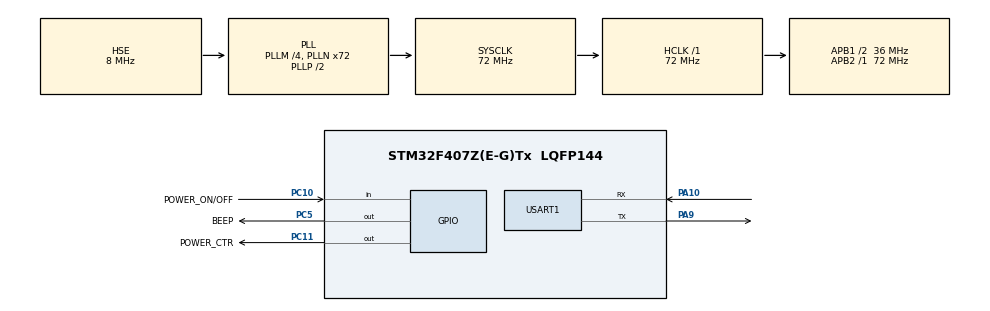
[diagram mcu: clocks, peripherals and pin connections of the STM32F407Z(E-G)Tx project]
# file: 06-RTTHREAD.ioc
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Mcu.Family=STM32F4
Mcu.Name=STM32F407Z(E-G)Tx
Mcu.Package=LQFP144
NVIC.PriorityGroup=NVIC_PRIORITYGROUP_4
NVIC.TIM7_IRQn=true\:15\:0\:false\:false\:true\:false\:false\:true\:true
NVIC.TimeBase=TIM7_IRQn
NVIC.TimeBaseIP=TIM7
NVIC.USART1_IRQn=true\:0\:0\:false\:false\:true\:false\:true\:true\:true
PA10.Mode=Asynchronous
PA10.Signal=USART1_RX
PA13.Mode=Serial_Wire
PA13.Signal=SYS_JTMS-SWDIO
PA14.Mode=Serial_Wire
PA14.Signal=SYS_JTCK-SWCLK
PA9.Mode=Asynchronous
PA9.Signal=USART1_TX
PC10.GPIO_Label=POWER_ON/OFF
PC10.GPIO_PuPd=GPIO_PULLUP
PC10.Signal=GPIO_Input
PC11.GPIO_Label=POWER_CTR
PC11.GPIO_PuPd=GPIO_PULLDOWN
PC11.GPIO_Speed=GPIO_SPEED_FREQ_HIGH
PC11.Signal=GPIO_Output
PC5.GPIO_Label=BEEP
PC5.GPIO_PuPd=GPIO_PULLDOWN
PC5.GPIO_Speed=GPIO_SPEED_FREQ_HIGH
PC5.Signal=GPIO_Output
PH0-OSC_IN.Mode=HSE-External-Oscillator
PH0-OSC_IN.Signal=RCC_OSC_IN
PH1-OSC_OUT.Mode=HSE-External-Oscillator
PH1-OSC_OUT.Signal=RCC_OSC_OUT
ProjectManager.HeapSize=0x200
ProjectManager.StackSize=0x400
ProjectManager.TargetToolchain=MDK-ARM V5.32
RCC.48MHZClocksFreq_Value=36000000
RCC.AHBFreq_Value=72000000
RCC.APB1CLKDivider=RCC_HCLK_DIV2
RCC.APB1Freq_Value=36000000
RCC.APB1TimFreq_Value=72000000
RCC.APB2Freq_Value=72000000
RCC.APB2TimFreq_Value=72000000
RCC.CortexFreq_Value=72000000
RCC.HCLKFreq_Value=72000000
RCC.HSE_VALUE=8000000
RCC.HSI_VALUE=16000000
RCC.LSE_VALUE=32768
RCC.PLLM=4
RCC.PLLN=72
RCC.PLLSourceVirtual=RCC_PLLSOURCE_HSE
RCC.SYSCLKFreq_VALUE=72000000
RCC.SYSCLKSource=RCC_SYSCLKSOURCE_PLLCLK
RCC.VCOOutputFreq_Value=144000000
RealThread.X-CUBE-RT-Thread_Nano.4.1.1.RTAaThreadCcRTOSJjkernel=true
RealThread.X-CUBE-RT-Thread_Nano.4.1.1.RTAaThreadCcRTOSJjlibcpu=true
RealThread.X-CUBE-RT-Thread_Nano.4.1.1.RTAaThreadCcRTOSJjshell=true
RealThread.X-CUBE-RT-Thread_Nano.4.1.1.RT_USING_FINSH=1
RealThread.X-CUBE-RT-Thread_Nano.4.1.1.RT_USING_HEAP=1
RealThread.X-CUBE-RT-Thread_Nano.4.1.1.RT_USING_SMALL_MEM=1
RealThread.X-CUBE-RT-Thread_Nano.4.1.1.RT_USING_SMALL_MEM_AS_HEAP=1
USART1.VirtualMode=VM_ASYNC
VP_RealThread.X-CUBE-RT-Thread_Nano_VS_RTOSJjRTAaThread_4.1.1_4.1.1.Mode=RTOSJjRTAaThread
VP_SYS_VS_tim7.Mode=TIM7
board=custom

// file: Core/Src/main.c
/* USER CODE BEGIN Header */
/**
  ******************************************************************************
  * @file           : main.c
  * @brief          : Main program body
  ******************************************************************************
  * @attention
  *
  * Copyright (c) 2024 STMicroelectronics.
  * All rights reserved.
  *
  * This software is licensed under terms that can be found in the LICENSE file
  * in the root directory of this software component.
  * If no LICENSE file comes with this software, it is provided AS-IS.
  *
  ******************************************************************************
  */
/* USER CODE END Header */
#include "main.h"
#include "usart.h"
#include "gpio.h"
#include "saple.h"

/* USER CODE BEGIN Includes */
#include <rtthread.h>
#include "PWR_ON.h"
#include "PWR_ON_OFF.h"

/* USER CODE END Includes */

void SystemClock_Config(void);

int main(void)
{

  /* USER CODE BEGIN 1 */
	rt_kprintf("hello,rtthread123!!!!\n");

  /* USER CODE END 1 */

  /* MCU Configuration--------------------------------------------------------*/

  /* Reset of all peripherals, Initializes the Flash interface and the Systick. */
  HAL_Init();

  /* Configure the system clock */
  SystemClock_Config();

  /* Initialize all configured peripherals */
  MX_GPIO_Init();
  MX_USART1_UART_Init();
  /* USER CODE BEGIN 2 */
  PWR_ON();
  thread_sample();

  /* USER CODE END 2 */

  /* Infinite loop */
  while (1)
  {

    /* USER CODE BEGIN 3 */
//	  PWR_ON_OFF();
	  rt_thread_mdelay(10);

  }
  /* USER CODE END 3 */
}

void SystemClock_Config(void)
{
  RCC_OscInitTypeDef RCC_OscInitStruct = {0};
  RCC_ClkInitTypeDef RCC_ClkInitStruct = {0};

  /** Configure the main internal regulator output voltage
  */
  __HAL_RCC_PWR_CLK_ENABLE();
  __HAL_PWR_VOLTAGESCALING_CONFIG(PWR_REGULATOR_VOLTAGE_SCALE1);

  /** Initializes the RCC Oscillators according to the specified parameters
  * in the RCC_OscInitTypeDef structure.
  */
  RCC_OscInitStruct.OscillatorType = RCC_OSCILLATORTYPE_HSE;
  RCC_OscInitStruct.HSEState = RCC_HSE_ON;
  RCC_OscInitStruct.PLL.PLLState = RCC_PLL_ON;
  RCC_OscInitStruct.PLL.PLLSource = RCC_PLLSOURCE_HSE;
  RCC_OscInitStruct.PLL.PLLM = 4;
  RCC_OscInitStruct.PLL.PLLN = 72;
  RCC_OscInitStruct.PLL.PLLP = RCC_PLLP_DIV2;
  RCC_OscInitStruct.PLL.PLLQ = 4;
  if (HAL_RCC_OscConfig(&RCC_OscInitStruct) != HAL_OK)
  {
    Error_Handler();
  }

  /** Initializes the CPU, AHB and APB buses clocks
  */
  RCC_ClkInitStruct.ClockType = RCC_CLOCKTYPE_HCLK|RCC_CLOCKTYPE_SYSCLK
                              |RCC_CLOCKTYPE_PCLK1|RCC_CLOCKTYPE_PCLK2;
  RCC_ClkInitStruct.SYSCLKSource = RCC_SYSCLKSOURCE_PLLCLK;
  RCC_ClkInitStruct.AHBCLKDivider = RCC_SYSCLK_DIV1;
  RCC_ClkInitStruct.APB1CLKDivider = RCC_HCLK_DIV2;
  RCC_ClkInitStruct.APB2CLKDivider = RCC_HCLK_DIV1;

  if (HAL_RCC_ClockConfig(&RCC_ClkInitStruct, FLASH_LATENCY_2) != HAL_OK)
  {
    Error_Handler();
  }
}

void HAL_TIM_PeriodElapsedCallback(TIM_HandleTypeDef *htim)
{
  if (htim->Instance == TIM7) {
    HAL_IncTick();
  }
}

void Error_Handler(void)
{
  __disable_irq();
  while (1)
  {
  }
}
